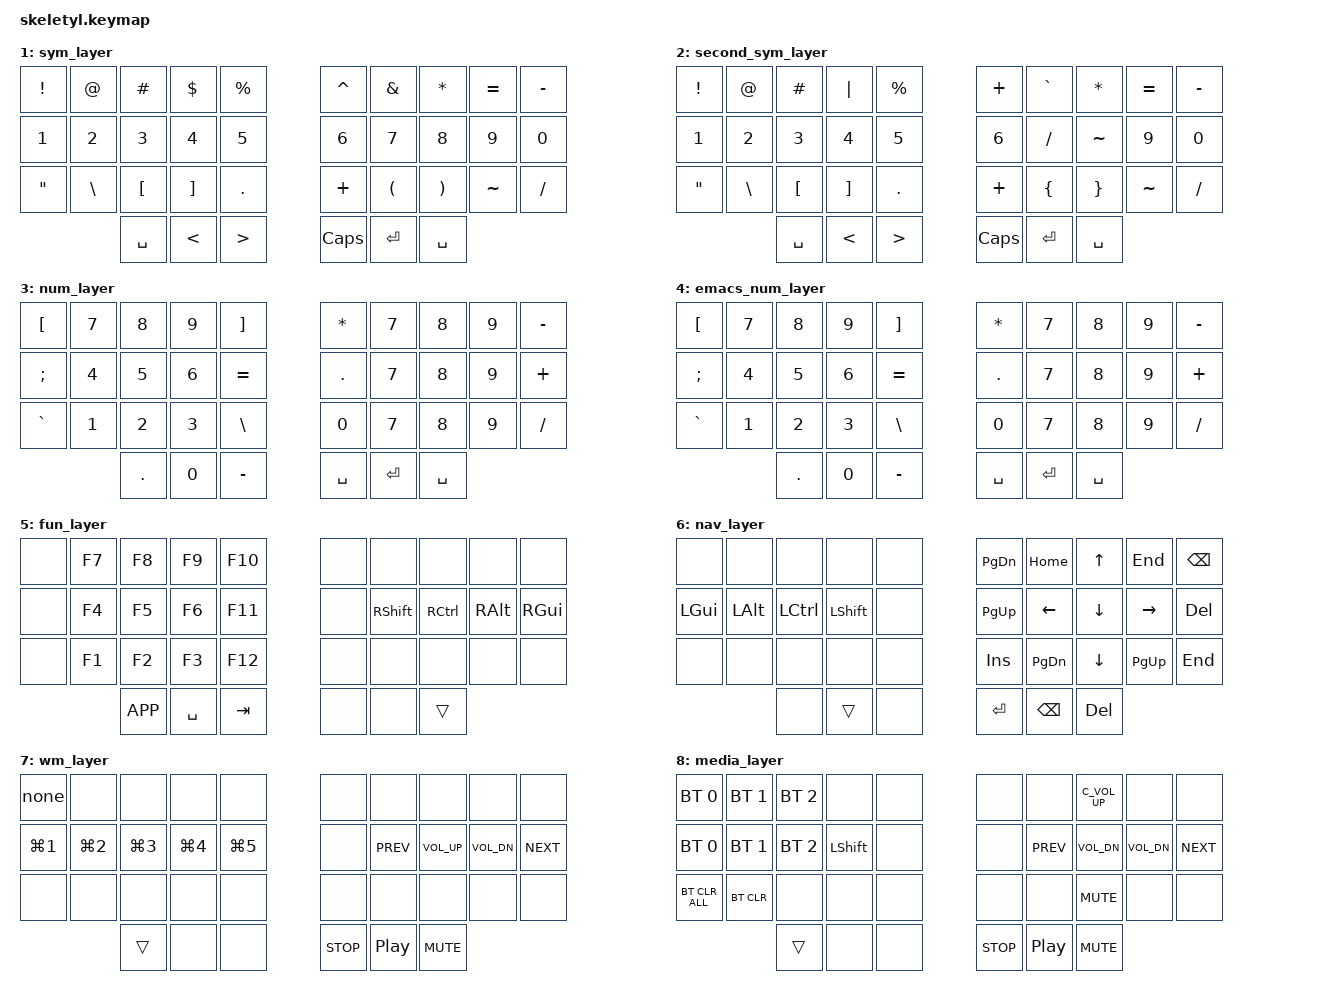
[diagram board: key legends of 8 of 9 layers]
#include <behaviors.dtsi>
#include <dt-bindings/zmk/keys.h>
#include <dt-bindings/zmk/bt.h>

// The default keymap is roughly on Miryoku layout
// (https://github.com/manna-harbour/miryoku).
// Customize on your own on the config folder.

#define DVORAK    0
#define SYM     1
#define SEC_SYM     2
#define NUMPAD     3
#define EMAC     4
#define FUN     5
#define NAV     6
#define WM     7
#define MEDIA     8

/ {
  combos {
        compatible = "zmk,combos";

        TAB_COMBO {
	  timeout-ms = <35>;
            bindings = <&kp TAB>;
            key-positions = <1 2>;
            layers = <0>;
        };

        CAPS_WORD_COMBO {
	  	  timeout-ms = <35>;
            bindings = <&caps_word>;
            key-positions = <27 28>;
            layers = <0>;
        };

        RETURN_COMBO  {
	  	  timeout-ms = <35>;
            bindings = <&kp ENTER>;
            key-positions = <26 27>;
            layers = <0>;
        };

        BACKSPACE_COMBO {
	  	  timeout-ms = <35>;
            bindings = <&kp BSPC>;
            key-positions = <6 7>;
            layers = <0>;
        };

        
    };
  
    behaviors {
        hm: homerow_mods {
            compatible = "zmk,behavior-hold-tap";
            label = "HOMEROW_MODS";
            #binding-cells = <2>;
            tapping-term-ms = <150>;
            quick-tap-ms = <0>;
            flavor = "hold-preferred";
            bindings = <&kp>, <&kp>;
        };
    };

    keymap {
        compatible = "zmk,keymap";

        default_layer {
            bindings = <
	      &kp SEMI &kp COMMA  &kp DOT  &kp P   &kp Y                       &kp F  &kp G  &kp C  &kp R  &kp L
    &hm LGUI A  &hm LALT O  &hm LCTRL E &hm LSHFT U &lt NAV I                      &lt FUN D  &hm LSHFT H &hm LCTRL T &hm LALT N      &hm LGUI S
    &kp SQT     &kp RALT Q  &lt EMAC J &lt SEC_SYM K  &kp X                    &kp B  &lt SEC_SYM M  &kp W   &kp V    &kp Z
                 &lt SYM ESC &lt NUMPAD TAB   &lt MEDIA TAB                    &lt WM ENTER &lt SYM ENTER    &lt SYM SPACE
            >;
        };
        sym_layer {
            bindings = <
    &kp EXCL    &kp AT    &kp HASH    &kp DOLLAR   &kp PERCENT                 &kp CARET &kp AMPS &kp STAR &kp EQUAL &kp MINUS 
    &kp N1   &kp N2    &kp N3   &kp N4  &kp N5                               &kp N6   &kp N7    &kp N8   &kp N9  &kp N0 
    &kp DQT   &kp BSLH    &kp LBKT      &kp RBKT   &kp DOT                    &kp PLUS   &kp LPAR    &kp RPAR      &kp TILDE   &kp FSLH
                                        &kp SPACE   &kp LT &kp GT           &kp CAPS   &kp ENTER &kp SPACE                                              
            >;
        };

	second_sym_layer {
            bindings = <
    &kp EXCL    &kp AT    &kp HASH    &kp PIPE   &kp PERCENT                 &kp PLUS &kp GRAVE &kp STAR &kp EQUAL &kp MINUS 
    &kp N1   &kp N2    &kp N3   &kp N4  &kp N5                               &kp N6   &kp FSLH    &kp TILDE   &kp N9  &kp N0 
    &kp DQT   &kp BSLH    &kp LBKT      &kp RBKT   &kp DOT                    &kp PLUS   &kp LBRC    &kp RBRC      &kp TILDE   &kp FSLH
                                        &kp SPACE   &kp LT &kp GT           &kp CAPS   &kp ENTER &kp SPACE                                              
            >;
        };
	num_layer {
            bindings = <
    &kp LBKT    &kp N7  &kp N8  &kp N9  &kp RBKT                        &kp STAR &kp N7  &kp N8  &kp N9  &kp MINUS 
    &kp SEMI    &kp N4  &kp N5  &kp N6  &kp EQUAL                       &kp DOT &kp N7  &kp N8  &kp N9  &kp PLUS
    &kp GRAVE   &kp N1  &kp N2  &kp N3  &kp BSLH                        &kp N0 &kp N7  &kp N8  &kp N9  &kp FSLH
                                &kp DOT &kp N0      &kp MINUS   &kp SPACE   &kp ENTER  &kp SPACE
	      
            >;
        };
	emacs_num_layer {
            bindings = <
    &kp LBKT    &kp N7  &kp N8  &kp N9  &kp RBKT                        &kp STAR &kp N7  &kp N8  &kp N9  &kp MINUS 
    &kp SEMI    &kp N4  &kp N5  &kp N6  &kp EQUAL                       &kp DOT &kp N7  &kp N8  &kp N9  &kp PLUS
    &kp GRAVE   &kp N1  &kp N2  &kp N3  &kp BSLH                        &kp N0 &kp N7  &kp N8  &kp N9  &kp FSLH
                                &kp DOT &kp N0      &kp MINUS   &kp SPACE   &kp ENTER  &kp SPACE
	      
            >;
        };
        fun_layer {
            bindings = <
     &none &kp F7  &kp F8  &kp F9 &kp F10                                 &none   &none       &none       &none       &none
     &none &kp F4  &kp F5  &kp F6 &kp F11                                  &none   &kp RSHFT   &kp RCTRL   &kp RALT    &kp RGUI
     &none &kp F1  &kp F2  &kp F3 &kp F12                       &none   &none       &none       &none       &none
                            &kp K_APP   &kp SPACE       &kp TAB     &none   &none   &trans
            >;
        };

        nav_layer {
            bindings = <
    &none       &none       &none       &none       &none                           &kp PG_DN    &kp HOME  &kp UP  &kp END &kp BSPC 
    &kp LGUI    &kp LALT    &kp LCTRL   &kp LSHFT   &none                           &kp PG_UP    &kp LEFT    &kp DOWN    &kp RIGHT       &kp DEL
    &none       &none       &none       &none       &none                           &kp INS     &kp PG_DN    &kp DOWN    &kp PG_UP   &kp END
                                        &none       &trans  &none       &kp RET     &kp BSPC    &kp DEL     
            >;
        };

	wm_layer {
            bindings = <
    &kp none       &none       &none       &none       &none                           &none       &none       &none           &none           &none
	      &kp LG(N1)    &kp LG(N2)     &kp LG(N3)   &kp LG(N4)   &kp LG(N5)     &none       &kp C_PREV  &kp C_VOL_UP    &kp C_VOL_DN    &kp C_NEXT
    &none       &none       &none       &none       &none                           &none       &none       &none           &none           &none
                                        &trans      &none   &none       &kp C_STOP  &kp C_PP    &kp C_MUTE     
            >;
        };

        

        media_layer {
            bindings = <
    &bt BT_SEL 0 &bt BT_SEL 1 &bt BT_SEL 2              &none       &none                           &none       &none       &C_VOL_UP           &none           &none
    &bt BT_SEL 0 &bt BT_SEL 1 &bt BT_SEL 2    &kp LSHFT   &none                           &none       &kp C_PREV  &kp C_VOL_DN    &kp C_VOL_DN    &kp C_NEXT
    &bt BT_CLR_ALL       &bt BT_CLR       &none       &none       &none                           &none       &none       & C_MUTE           &none           &none
                                        &trans      &none   &none       &kp C_STOP  &kp C_PP    &kp C_MUTE     
            >;
        };

    }
	;
};
